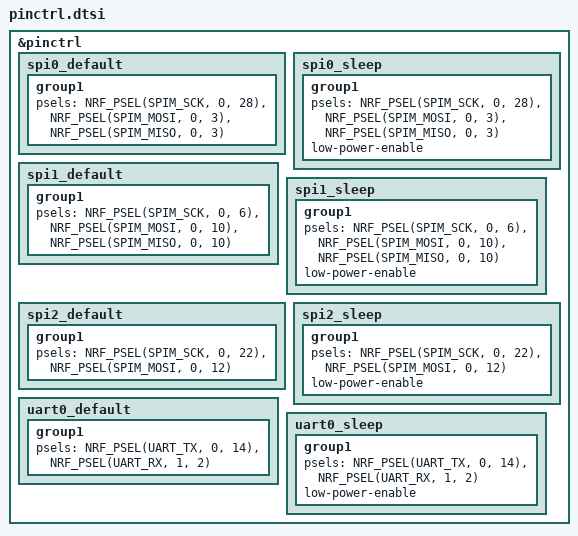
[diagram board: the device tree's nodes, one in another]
&pinctrl {
//    i2c0_default: i2c0_default {
//        group1 {
//            psels = <NRF_PSEL(TWIM_SDA, 0, 25)>,
//                    <NRF_PSEL(TWIM_SCL, 0, 23)>;
//        };
//    };
//
//    i2c0_sleep: i2c0_sleep {
//        group1 {
//            psels = <NRF_PSEL(TWIM_SDA, 0, 25)>,
//                    <NRF_PSEL(TWIM_SCL, 0, 23)>;
//            low-power-enable;
//        };
//    };

    spi0_default: spi0_default {
        group1 {
            psels = <NRF_PSEL(SPIM_SCK, 0, 28)>,
                    <NRF_PSEL(SPIM_MOSI, 0, 3)>,
                    <NRF_PSEL(SPIM_MISO, 0, 3)>;
        };
    };

    spi0_sleep: spi0_sleep {
        group1 {
            psels = <NRF_PSEL(SPIM_SCK, 0, 28)>,
                    <NRF_PSEL(SPIM_MOSI, 0, 3)>,
                    <NRF_PSEL(SPIM_MISO, 0, 3)>;
            low-power-enable;
        };
    };

    spi1_default: spi1_default {
        group1 {
            psels = <NRF_PSEL(SPIM_SCK, 0, 6)>,
                    <NRF_PSEL(SPIM_MOSI, 0, 10)>,
                    <NRF_PSEL(SPIM_MISO, 0, 10)>;
        };
    };

    spi1_sleep: spi1_sleep {
        group1 {
            psels = <NRF_PSEL(SPIM_SCK, 0, 6)>,
                    <NRF_PSEL(SPIM_MOSI, 0, 10)>,
                    <NRF_PSEL(SPIM_MISO, 0, 10)>;
            low-power-enable;
        };
    };

    spi2_default: spi2_default {
        group1 {
            psels = <NRF_PSEL(SPIM_SCK, 0, 22)>,
                    <NRF_PSEL(SPIM_MOSI, 0, 12)>;
        };
    };

    spi2_sleep: spi2_sleep {
        group1 {
            psels = <NRF_PSEL(SPIM_SCK, 0, 22)>,
                    <NRF_PSEL(SPIM_MOSI, 0, 12)>;
            low-power-enable;
        };
    };

    uart0_default: uart0_default {
        group1 {
			psels = <NRF_PSEL(UART_TX, 0, 14)>,
                    <NRF_PSEL(UART_RX, 1, 2)>;
        };
    };

    uart0_sleep: uart0_sleep {
        group1 {
            psels = <NRF_PSEL(UART_TX, 0, 14)>,
                    <NRF_PSEL(UART_RX, 1, 2)>;
            low-power-enable;
        };
    };
};
